# pwrseq_me21 register map
Registers are read-write, no defined reset value unless marked. A register's access mark holds for its fields unless they carry their own. Offsets are from the block's base; lines under a group give offsets from that group; [hi:lo] are bit positions; {n}, {i} and the like mark numbered series; 'fields as' and 'values as' point back to an identical list; <NAME> marks a mode.

## Memory map
0x40106800 PWRSEQ size 0x400 — Power Sequencer / Low Power Control Register.

## PWRSEQ — Power Sequencer / Low Power Control Register.
Base 0x40106800
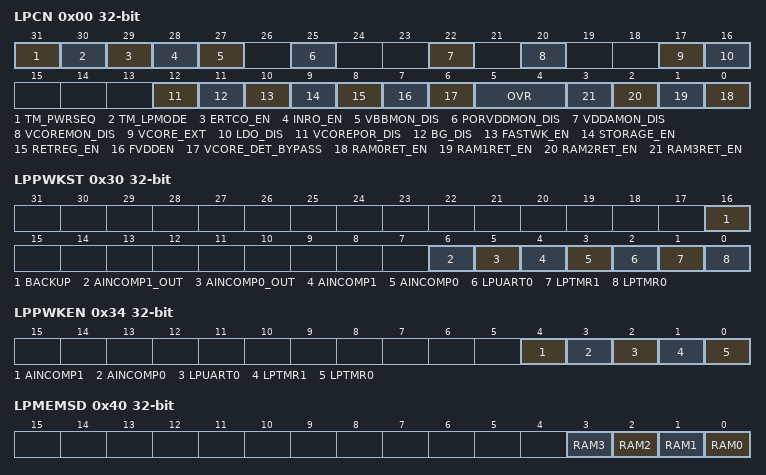
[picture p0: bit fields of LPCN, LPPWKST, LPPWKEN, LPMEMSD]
0x00 LPCN — Low Power Control Register.
  [31] TM_PWRSEQ
  [30] TM_LPMODE
  [29] ERTCO_EN — XRTCO remains on in all power modes if this bit is set otherwise it is controled by the LP controller
  [28] INRO_EN — INRO remains on in all power modes if this bit is set otherwise it is controled by the LP controller
  [27] VBBMON_DIS — VBB Monitor Disable. This bit controls the power monitor of the Analog Supply in all operating modes.
    0=en (Enable if Bandgap is ON (default)); 1=dis (Disabled.)
  [25] PORVDDMON_DIS — VDDIO Power-On Reset Monitor Disable. This bit controls the Power-On Reset monitor on VDDIO supply in all operating mods.
    0=dis (Disabled.); 1=en (Enabled.)
  [22] VDDAMON_DIS — VDDA Monitor Disable. This bit controls the power monitor of the Analog Supply in all operating modes.
    0=en (Enable if Bandgap is ON (default)); 1=dis (Disabled.)
  [20] VCOREMON_DIS — VDDC (Vcore) Monitor Disable. This bit controls the power monitor on the VCore supply in all operating modes.
    0=en (Enable); 1=dis (Disabled.)
  [17] VCORE_EXT — Use external VCORE for 1V supply
    0=dis (disable); 1=en (use Vcore for retention.)
  [16] LDO_DIS — Disable Main LDO
    0=en (Enable); 1=dis (Disabled.)
  [12] VCOREPOR_DIS — VDDC (Vcore) Power on reset Monitor Disable.This bit controls the Power-On Reset monitor on VDDC supply in DeepSleep and BACKUP mode.
    0=en (Enable); 1=dis (Disabled.)
  [11] BG_DIS — Bandgap OFF. This controls the System Bandgap in DeepSleep mode.
    0=on (Bandgap is always ON.); 1=off (Bandgap is OFF in DeepSleep mode (default).)
  [10] FASTWK_EN — Fast Wake-Up Mode. This bit enables fast wake-up from DeepSleep mode. (5uS typical).
    0=dis (Disabled.); 1=en (Enabled.)
  [9] STORAGE_EN — STORAGE Mode ENable. This bit allows low-power background mode operations, while the CPU is in DeepSleep.
    0=dis (Disabled.); 1=en (Enabled.)
  [8] RETREG_EN — Retention Regulator Enable. This bit controls the retention regulator in BACKUP mode.
    0=dis (Disabled.); 1=en (Enabled.)
  [7] FVDDEN — Flash VDD Enable, force the flash VDD to remain enabled during LP modes.
    0=dis (enable); 1=en (disable)
  [6] VCORE_DET_BYPASS — Block Auto-Detect
    0=en (enable); 1=dis (disable)
  [5:4] OVR — Operating Voltage Range
    0=0_9V (0.9V 12MHz); 1=1_0V (1.0V 48MHz); 2=1_1V (1.1V 96MHz)
  [n] RAM{n}RET_EN (n=0..3) — System RAM retention in BACKUP mode. These two bits are used in conjuction with RREGEN bit.
    0=dis (Disable Ram Retention.); 1=en (Enable System RAM {n} retention.)
0x04 LPWKST0 — Low Power I/O Wakeup Status Register 0. This register indicates the low power wakeup status for GPIO0.
  [30:0] ST write-1-clears — Wakeup IRQ flags (write ones to clear). One or more of these bits will be set when the corresponding dedicated GPIO pin (s) transition (s) from low to high or high to low. If GPIO wakeup source is selected, using PM.GPIOWKEN register, and the corresponding bit is also selected in LPWKEN register, an interrupt will be gnerated to wake up the CPU from a low power mode.
0x08 LPWKEN0 — Low Power I/O Wakeup Enable Register 0. This register enables low power wakeup functionality for GPIO0.
  [30:0] EN — Enable wakeup. These bits allow wakeup from the corresponding GPIO pin (s) on transition (s) from low to high or high to low when PM.GPIOWKEN is set. Wakeup status is indicated in PPWKST register.
0x0C LPWKST1 — Low Power I/O Wakeup Status Register 1. This register indicates the low power wakeup status for GPIO1.
  fields as LPWKST0
0x10 LPWKEN1 — Low Power I/O Wakeup Enable Register 1. This register enables low power wakeup functionality for GPIO1.
  fields as LPWKEN0
0x30 LPPWKST access per field — Low Power Peripheral Wakeup Status Register.
  [16] BACKUP rw write-1-clears — BBMODE Wakeup Flag.
  [6] AINCOMP1_OUT ro — AINCOMP1 Status.
  [5] AINCOMP0_OUT ro — AINCOMP0 Status.
  [4] AINCOMP1 rw write-1-clears — AINCOMP1 Wakeup Flag.
  [3] AINCOMP0 rw write-1-clears — AINCOMP0 Wakeup Flag.
  [2] LPUART0 rw write-1-clears — LPUART0 Wakeup Flag.
  [1] LPTMR1 rw write-1-clears — LPTMR1 Wakeup Flag.
  [0] LPTMR0 rw write-1-clears — LPTM0 Wakeup Flag.
0x34 LPPWKEN — Low Power Peripheral Wakeup Enable Register.
  [4] AINCOMP1 — AINCOMP1 Wakeup Enable. This bit allows wakeup from the AINCOMP1.
  [3] AINCOMP0 — AINCOMP0 Wakeup Enable. This bit allows wakeup from the AINCOMP0.
  [2] LPUART0 — LPUART Wakeup Enable. This bit allows wakeup from the LPUART.
  [1] LPTMR1 — TIMER5 Wakeup Enable. This bit allows wakeup from the TIMER5.
  [0] LPTMR0 — TIMER4 Wakeup Enable. This bit allows wakeup from the TIMER4.
0x40 LPMEMSD — Low Power Memory Shutdown Control.
  [all] fields
    0=Normal Operating Mode; 1=Shutdown Mode
  [n] RAM{n} (n=0..3) — System RAM block {n} Shut Down.
0x48 GPR0 access not given — General Purpose Register 0.
0x4C GPR1 access not given — General Purpose Register 1.
